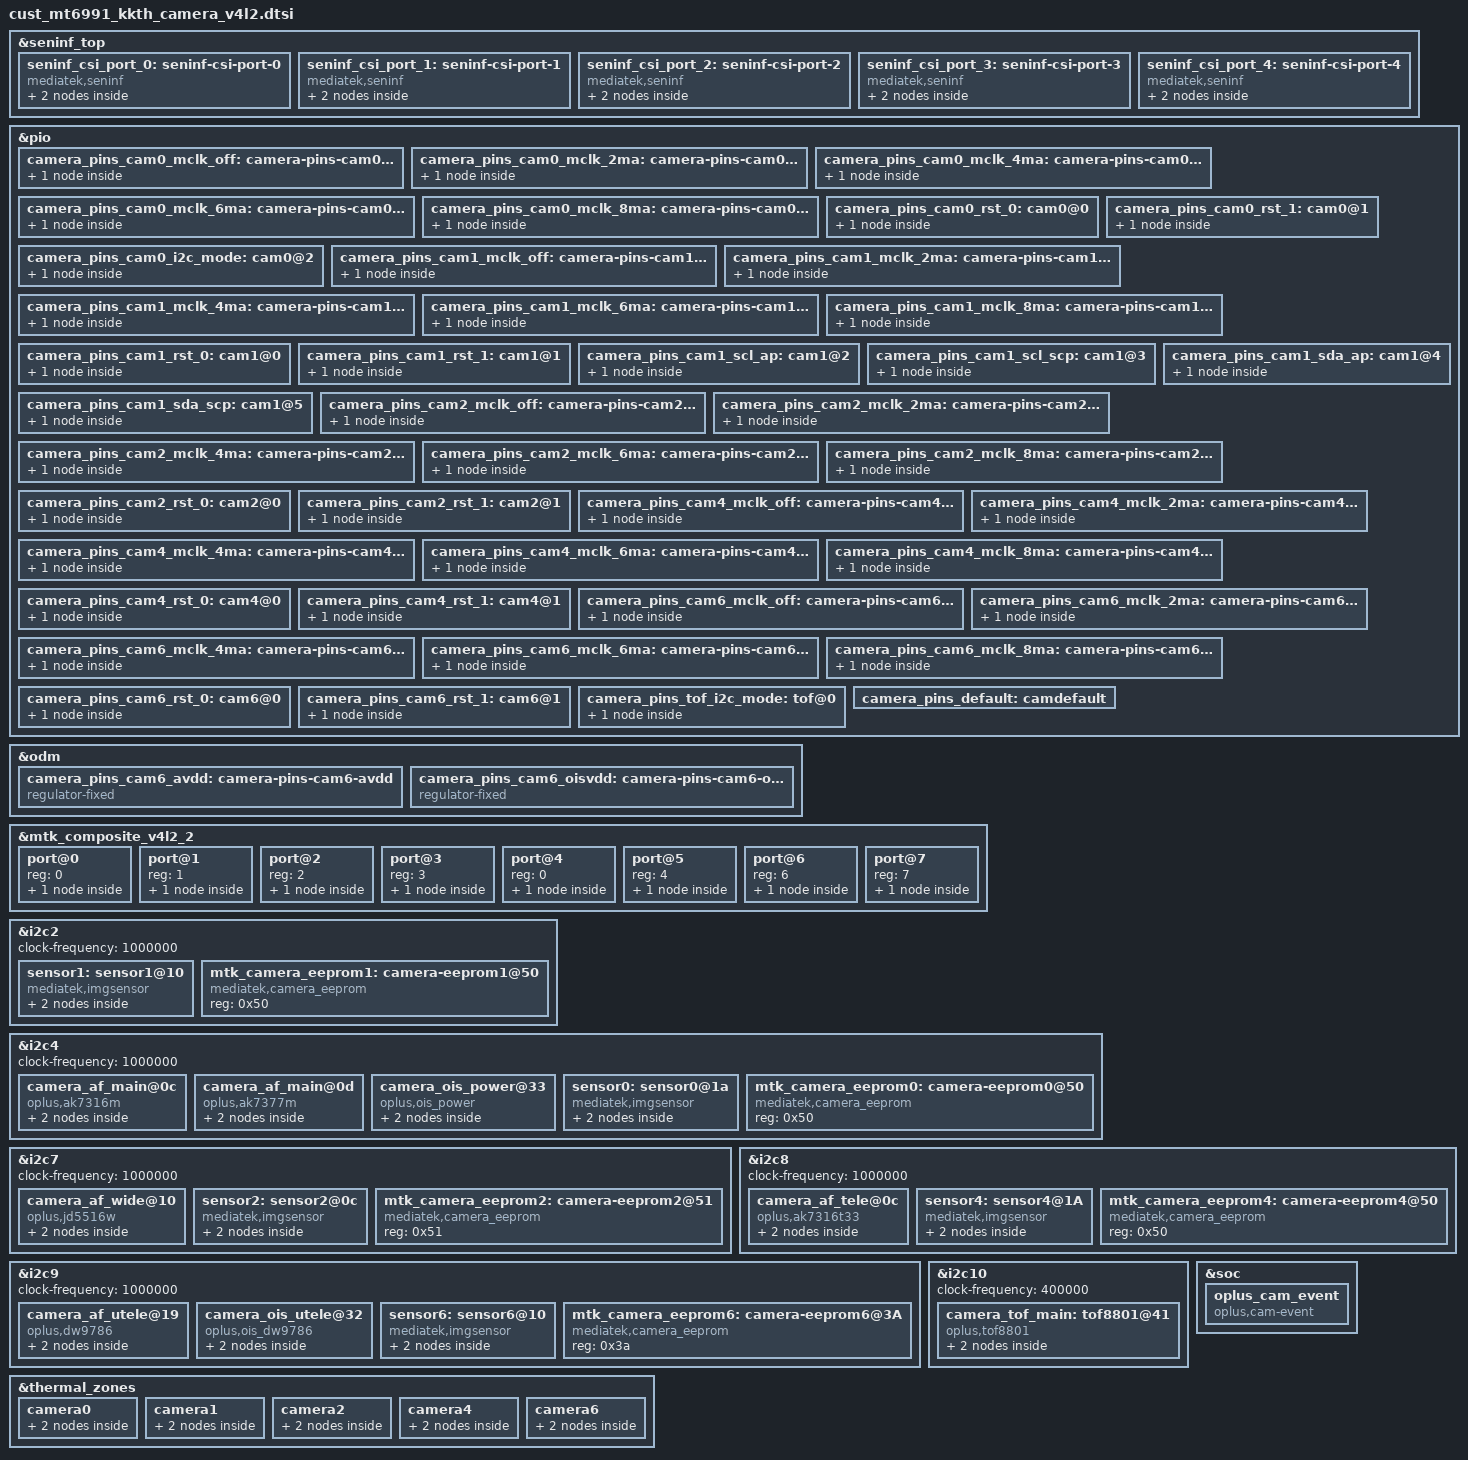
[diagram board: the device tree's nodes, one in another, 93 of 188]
// SPDX-License-Identifier: GPL-2.0
/* Copyright (c) 2023 MediaTek Inc. */
#include <dt-bindings/clock/mt6991-clk.h>
#include "mediatek/konka_regulator.dtsi"
// #include "mediatek/mt6373.dtsi"
&seninf_top {
		seninf_csi_port_0: seninf-csi-port-0 {
			compatible = "mediatek,seninf";
			csi-port = "0";

			// nvmem-cells = <&csi_efuse0>;
			nvmem-cell-names = "rg_csi";

			port {
				seninf_csi_port_0_in: endpoint {
					remote-endpoint = <&sensor0_out>;
				};
			};
		};

		seninf_csi_port_1: seninf-csi-port-1 {
			compatible = "mediatek,seninf";
			csi-port = "1";

			// nvmem-cells = <&csi_efuse1>;
			nvmem-cell-names = "rg_csi";

			port {
				seninf_csi_port_1_in: endpoint {
					remote-endpoint = <&sensor6_out>;
				};
			};
		};

		seninf_csi_port_2: seninf-csi-port-2 {
			compatible = "mediatek,seninf";
			csi-port = "2";

			// nvmem-cells = <&csi_efuse2>;
			nvmem-cell-names = "rg_csi";

			port {
				seninf_csi_port_2_in: endpoint {
					remote-endpoint = <&sensor4_out>;
				};
			};
		};
		seninf_csi_port_3: seninf-csi-port-3 {
			compatible = "mediatek,seninf";
			csi-port = "3";

			// nvmem-cells = <&csi_efuse3>;
			nvmem-cell-names = "rg_csi";

			port {
				seninf_csi_port_3_in: endpoint {
					remote-endpoint = <&sensor1_out>;
				};
			};
		};
		seninf_csi_port_4: seninf-csi-port-4 {
			compatible = "mediatek,seninf";
			csi-port = "4";

			// nvmem-cells = <&csi_efuse4>;
			nvmem-cell-names = "rg_csi";

			port {
				seninf_csi_port_4_in: endpoint {
					remote-endpoint = <&sensor2_out>;
				};
			};
		};
};

/* CAMERA GPIO standardization */
&pio {
	camera_pins_cam0_mclk_off: camera-pins-cam0-mclk-off {
		pins-cmd-dat {
			pinmux = <PINMUX_GPIO210__FUNC_GPIO210>;
			drive-strength = <1>;
		};
	};
	camera_pins_cam0_mclk_2ma: camera-pins-cam0-mclk-2ma {
		pins-cmd-dat {
			pinmux = <PINMUX_GPIO210__FUNC_CMMCLK4>;
			drive-strength = <0>;
		};
	};
	camera_pins_cam0_mclk_4ma: camera-pins-cam0-mclk-4ma {
		pins-cmd-dat {
			pinmux = <PINMUX_GPIO210__FUNC_CMMCLK4>;
			drive-strength = <1>;
		};
	};
	camera_pins_cam0_mclk_6ma: camera-pins-cam0-mclk-6ma {
		pins-cmd-dat {
			pinmux = <PINMUX_GPIO210__FUNC_CMMCLK4>;
			drive-strength = <2>;
		};
	};
	camera_pins_cam0_mclk_8ma: camera-pins-cam0-mclk-8ma {
		pins-cmd-dat {
			pinmux = <PINMUX_GPIO210__FUNC_CMMCLK4>;
			drive-strength = <3>;
		};
	};
	camera_pins_cam0_rst_0: cam0@0 {
		pins-cmd-dat {
			pinmux = <PINMUX_GPIO187__FUNC_GPIO187>;
			slew-rate = <1>;
			output-low;
		};
	};
	camera_pins_cam0_rst_1: cam0@1 {
		pins-cmd-dat {
			pinmux = <PINMUX_GPIO187__FUNC_GPIO187>;
			slew-rate = <1>;
			output-high;
		};
	};
	camera_pins_cam0_i2c_mode: cam0@2 {
		pins-cmd-dat {
			pinmux = <PINMUX_GPIO190__FUNC_SCL4>,
			<PINMUX_GPIO191__FUNC_SDA4>;
			bias-pull-up;
			input-enable;
		};
	};
	camera_pins_cam1_mclk_off: camera-pins-cam1-mclk-off {
		pins-cmd-dat {
			pinmux = <PINMUX_GPIO79__FUNC_GPIO79>;
			drive-strength = <1>;
		};
	};
	camera_pins_cam1_mclk_2ma: camera-pins-cam1-mclk-2ma {
		pins-cmd-dat {
			pinmux = <PINMUX_GPIO79__FUNC_CMMCLK0>;
			drive-strength = <0>;
		};
	};
	camera_pins_cam1_mclk_4ma: camera-pins-cam1-mclk-4ma {
		pins-cmd-dat {
			pinmux = <PINMUX_GPIO79__FUNC_CMMCLK0>;
			drive-strength = <1>;
		};
	};
	camera_pins_cam1_mclk_6ma: camera-pins-cam1-mclk-6ma {
		pins-cmd-dat {
			pinmux = <PINMUX_GPIO79__FUNC_CMMCLK0>;
			drive-strength = <2>;
		};
	};
	camera_pins_cam1_mclk_8ma: camera-pins-cam1-mclk-8ma {
		pins-cmd-dat {
			pinmux = <PINMUX_GPIO79__FUNC_CMMCLK0>;
			drive-strength = <3>;
		};
	};
	camera_pins_cam1_rst_0: cam1@0 {
		pins-cmd-dat {
			pinmux = <PINMUX_GPIO186__FUNC_GPIO186>;
			slew-rate = <1>;
			output-low;
		};
	};
	camera_pins_cam1_rst_1: cam1@1 {
		pins-cmd-dat {
			pinmux = <PINMUX_GPIO186__FUNC_GPIO186>;
			slew-rate = <1>;
			output-high;
		};
	};
	camera_pins_cam1_scl_ap: cam1@2 {
		pins-cmd-dat {
			pinmux = <PINMUX_GPIO188__FUNC_SCL2>;
		};
	};
	camera_pins_cam1_scl_scp: cam1@3 {
		pins-cmd-dat {
			pinmux = <PINMUX_GPIO188__FUNC_SCP_SCL8>;
		};
	};
	camera_pins_cam1_sda_ap: cam1@4 {
		pins-cmd-dat {
			pinmux = <PINMUX_GPIO189__FUNC_SDA2>;
		};
	};
	camera_pins_cam1_sda_scp: cam1@5 {
		pins-cmd-dat {
			pinmux = <PINMUX_GPIO189__FUNC_SCP_SDA8>;
		};
	};
	camera_pins_cam2_mclk_off: camera-pins-cam2-mclk-off {
		pins-cmd-dat {
			pinmux = <PINMUX_GPIO196__FUNC_GPIO196>;
			drive-strength = <1>;
		};
	};
	camera_pins_cam2_mclk_2ma: camera-pins-cam2-mclk-2ma {
		pins-cmd-dat {
			pinmux = <PINMUX_GPIO196__FUNC_CMMCLK3>;
			drive-strength = <0>;
		};
	};
	camera_pins_cam2_mclk_4ma: camera-pins-cam2-mclk-4ma {
		pins-cmd-dat {
			pinmux = <PINMUX_GPIO196__FUNC_CMMCLK3>;
			drive-strength = <1>;
		};
	};
	camera_pins_cam2_mclk_6ma: camera-pins-cam2-mclk-6ma {
		pins-cmd-dat {
			pinmux = <PINMUX_GPIO196__FUNC_CMMCLK3>;
			drive-strength = <2>;
		};
	};
	camera_pins_cam2_mclk_8ma: camera-pins-cam2-mclk-8ma {
		pins-cmd-dat {
			pinmux = <PINMUX_GPIO196__FUNC_CMMCLK3>;
			drive-strength = <3>;
		};
	};
	camera_pins_cam2_rst_0: cam2@0 {
		pins-cmd-dat {
			pinmux = <PINMUX_GPIO206__FUNC_GPIO206>;
			slew-rate = <1>;
			output-low;
		};
	};
	camera_pins_cam2_rst_1: cam2@1 {
		pins-cmd-dat {
			pinmux = <PINMUX_GPIO206__FUNC_GPIO206>;
			slew-rate = <1>;
			output-high;
		};
	};

	camera_pins_cam4_mclk_off: camera-pins-cam4-mclk-off {
		pins-cmd-dat {
			pinmux = <PINMUX_GPIO80__FUNC_GPIO80>;
			drive-strength = <1>;
		};
	};
	camera_pins_cam4_mclk_2ma: camera-pins-cam4-mclk-2ma {
		pins-cmd-dat {
			pinmux = <PINMUX_GPIO192__FUNC_CMMCLK2>;
			drive-strength = <0>;
		};
	};
	camera_pins_cam4_mclk_4ma: camera-pins-cam4-mclk-4ma {
		pins-cmd-dat {
			pinmux = <PINMUX_GPIO192__FUNC_CMMCLK2>;
			drive-strength = <1>;
		};
	};
	camera_pins_cam4_mclk_6ma: camera-pins-cam4-mclk-6ma {
		pins-cmd-dat {
			pinmux = <PINMUX_GPIO192__FUNC_CMMCLK2>;
			drive-strength = <2>;
		};
	};
	camera_pins_cam4_mclk_8ma: camera-pins-cam4-mclk-8ma {
		pins-cmd-dat {
			pinmux = <PINMUX_GPIO192__FUNC_CMMCLK2>;
			drive-strength = <3>;
		};
	};
	camera_pins_cam4_rst_0: cam4@0 {
		pins-cmd-dat {
			pinmux = <PINMUX_GPIO197__FUNC_GPIO197>;
			slew-rate = <1>;
			output-low;
		};
	};
	camera_pins_cam4_rst_1: cam4@1 {
		pins-cmd-dat {
			pinmux = <PINMUX_GPIO197__FUNC_GPIO197>;
			slew-rate = <1>;
			output-high;
		};
	};

	camera_pins_cam6_mclk_off: camera-pins-cam6-mclk-off {
		pins-cmd-dat {
			pinmux = <PINMUX_GPIO80__FUNC_GPIO80>;
			drive-strength = <1>;
		};
	};
	camera_pins_cam6_mclk_2ma: camera-pins-cam6-mclk-2ma {
		pins-cmd-dat {
			pinmux = <PINMUX_GPIO80__FUNC_CMMCLK1>;
			drive-strength = <0>;
		};
	};
	camera_pins_cam6_mclk_4ma: camera-pins-cam6-mclk-4ma {
		pins-cmd-dat {
			pinmux = <PINMUX_GPIO80__FUNC_CMMCLK1>;
			drive-strength = <1>;
		};
	};
	camera_pins_cam6_mclk_6ma: camera-pins-cam6-mclk-6ma {
		pins-cmd-dat {
			pinmux = <PINMUX_GPIO80__FUNC_CMMCLK1>;
			drive-strength = <2>;
		};
	};
	camera_pins_cam6_mclk_8ma: camera-pins-cam6-mclk-8ma {
		pins-cmd-dat {
			pinmux = <PINMUX_GPIO80__FUNC_CMMCLK1>;
			drive-strength = <3>;
		};
	};
	camera_pins_cam6_rst_0: cam6@0 {
		pins-cmd-dat {
			pinmux = <PINMUX_GPIO193__FUNC_GPIO193>;
			slew-rate = <1>;
			output-low;
		};
	};
	camera_pins_cam6_rst_1: cam6@1 {
		pins-cmd-dat {
			pinmux = <PINMUX_GPIO193__FUNC_GPIO193>;
			slew-rate = <1>;
			output-high;
		};
	};
	camera_pins_tof_i2c_mode: tof@0 {
		pins-cmd-dat {
			pinmux = <PINMUX_GPIO101__FUNC_SCL10>,
			<PINMUX_GPIO102__FUNC_SDA10>,
			<PINMUX_GPIO21__FUNC_GPIO21>;
			bias-pull-up;
			input-enable;
		};
	};
	camera_pins_default: camdefault {
	};
};
/* CAMERA GPIO end */

&odm {
	camera_pins_cam6_avdd: camera-pins-cam6-avdd {
		compatible = "regulator-fixed";
		regulator-name = "camera-pins-cam6-avdd";
		regulator-min-microvolt = <2800000>;
		regulator-max-microvolt = <2800000>;
		enable-active-high;
		gpio = <&pio 183 0x0>;
	};
	camera_pins_cam6_oisvdd: camera-pins-cam6-oisvdd {
		compatible = "regulator-fixed";
		regulator-name = "camera-pins-cam6-oisvdd";
		regulator-min-microvolt = <3100000>;
		regulator-max-microvolt = <3100000>;
		enable-active-high;
		gpio = <&pio 180 0x0>;
	};
};

&mtk_composite_v4l2_2 {

	#address-cells = <1>;
	#size-cells = <0>;

	port@0 {
		reg = <0>;
		main_af_endpoint: endpoint {
			remote-endpoint = <&main_af>;
		};
	};
	port@1 {
		reg = <1>;
		wide_af_endpoint: endpoint {
			remote-endpoint = <&wide_af>;
		};
	};
	port@2 {
		reg = <2>;
		tele_af_endpoint: endpoint {
			remote-endpoint = <&tele_af>;
		};
	};
	port@3 {
		reg = <3>;
		utele_af_endpoint: endpoint {
			remote-endpoint = <&utele_af>;
		};
	};
	port@4 {
		reg = <0>;
		main_tof_endpoint: endpoint {
			remote-endpoint = <&main_tof>;
		};
	};
	port@5 {
		reg = <4>;
		utele_ois_endpoint: endpoint {
			remote-endpoint = <&utele_ois>;
		};
	};
	port@6 {
		reg = <6>;
		main_af2_endpoint: endpoint {
			remote-endpoint = <&main_af2>;
		};
	};
	port@7 {
		reg = <7>;
		ois_power_endpoint: endpoint {
			remote-endpoint = <&ois_power>;
		};
	};
};


&i2c2 {
	status = "okay";
	clock-frequency = <1000000>;
	#address-cells = <1>;
	#size-cells = <0>;

	sensor1: sensor1@10 {
		compatible = "mediatek,imgsensor";
		sensor-names = "kkthfront_mipi_raw";
		reg = <0x10>;
		#thermal-sensor-cells = <0>;

		pinctrl-names = "mclk_off",
				"mclk_2mA",
				"mclk_4mA",
				"mclk_6mA",
				"mclk_8mA",
				"rst_low",
				"rst_high",
				"scl_ap",
				"scl_scp",
				"sda_ap",
				"sda_scp";

		pinctrl-0 = <&camera_pins_cam1_mclk_off>;
		pinctrl-1 = <&camera_pins_cam1_mclk_2ma>;
		pinctrl-2 = <&camera_pins_cam1_mclk_4ma>;
		pinctrl-3 = <&camera_pins_cam1_mclk_6ma>;
		pinctrl-4 = <&camera_pins_cam1_mclk_8ma>;
		pinctrl-5 = <&camera_pins_cam1_rst_0>;
		pinctrl-6 = <&camera_pins_cam1_rst_1>;
		pinctrl-7 = <&camera_pins_cam1_scl_ap>;
		pinctrl-8 = <&camera_pins_cam1_scl_scp>;
		pinctrl-9 = <&camera_pins_cam1_sda_ap>;
		pinctrl-10 = <&camera_pins_cam1_sda_scp>;

		avdd-supply = <&wl28681c_konka_ldo3a>;
		dvdd-supply = <&wl28681c_konka_ldo1a>;
		dovdd-supply = <&mt6373_vrf18_aif>;

		clocks =<&cksys_clk CLK_CK_UNIVPLL_192M_D32>,
			<&cksys_clk CLK_CK_UNIVPLL_192M_D16>,
			<&cksys_clk CLK_CK_F26M_CK_D2>,
			<&cksys_clk CLK_CK_UNIVPLL_192M_D10>,
			<&cksys_clk CLK_CK_UNIVPLL_192M_D8>,
			<&cksys_clk CLK_CK_UNIVPLL_D6_D16>,
			<&cksys_clk CLK_CK_OSC3>,
			<&cksys_clk CLK_CK_UNIVPLL_D6_D8>,
			<&vlp_cksys_clk CLK_VLP_CK_CAMTG0_SEL>;
		clock-names ="6", "12", "13", "19.2",
			"24", "26", "26_ulposc", "52", "mclk";

		status = "okay";
		port {
			sensor1_out: endpoint {
				remote-endpoint = <&seninf_csi_port_3_in>;
			};
		};
	};

	mtk_camera_eeprom1:camera-eeprom1@50 {
		compatible = "mediatek,camera_eeprom";
		reg = <0x50>;
		status = "okay";
	};
};


&i2c4 {
	status = "okay";
	clock-frequency = <1000000>;
	#address-cells = <1>;
	#size-cells = <0>;

	camera_af_main@0c {
		compatible = "oplus,ak7316m";
		reg = <0x0c>;
		vin-supply = <&mt6373_vcn33_3>;
		port {
			main_af: endpoint {
				remote-endpoint = <&main_af_endpoint>;
			};
		};
	};

	camera_af_main@0d {
		compatible = "oplus,ak7377m";
		reg = <0x0d>;
		vin-supply = <&mt6373_vcn33_3>;
		port {
			main_af2: endpoint {
				remote-endpoint = <&main_af2_endpoint>;
			};
		};
	};

	camera_ois_power@33 {
		compatible = "oplus,ois_power";
		reg = <0x33>;
		ois1-supply = <&mt6373_vcn33_3>;
		ois2-supply = <&mt6373_vcn33_2>;
		port {
			ois_power: endpoint {
				remote-endpoint = <&ois_power_endpoint>;
			};
		};
	};

	sensor0: sensor0@1a {
		compatible = "mediatek,imgsensor";
		sensor-names = "kkthmain_mipi_raw";
		reg = <0x1a>;
		#thermal-sensor-cells = <0>;

		pinctrl-names = "mclk_off",
				"mclk_2mA",
				"mclk_4mA",
				"mclk_6mA",
				"mclk_8mA",
				"rst_low",
				"rst_high",
				"default";
		pinctrl-0 = <&camera_pins_cam0_mclk_off>;
		pinctrl-1 = <&camera_pins_cam0_mclk_2ma>;
		pinctrl-2 = <&camera_pins_cam0_mclk_4ma>;
		pinctrl-3 = <&camera_pins_cam0_mclk_6ma>;
		pinctrl-4 = <&camera_pins_cam0_mclk_8ma>;
		pinctrl-5 = <&camera_pins_cam0_rst_0>;
		pinctrl-6 = <&camera_pins_cam0_rst_1>;
		pinctrl-7 = <&camera_pins_cam0_i2c_mode>;

		avdd1-supply = <&wl28681c_konka_ldo7a>;
		avdd-supply = <&wl28681c_konka_ldo4a>;
		dvdd-supply = <&wl28681c_konka_ldo2a>;
		dovdd-supply = <&mt6373_vrf18_aif>;
		afvdd-supply = <&mt6373_vcn33_3>;

		clocks = <&cksys_clk CLK_CK_UNIVPLL_192M_D32>,
			<&cksys_clk CLK_CK_UNIVPLL_192M_D16>,
			<&cksys_clk CLK_CK_F26M_CK_D2>,
			<&cksys_clk CLK_CK_UNIVPLL_192M_D10>,
			<&cksys_clk CLK_CK_UNIVPLL_192M_D8>,
			<&cksys_clk CLK_CK_UNIVPLL_D6_D16>,
			<&cksys_clk CLK_CK_UNIVPLL_D6_D8>,
			<&vlp_cksys_clk CLK_VLP_CK_CAMTG4_SEL>;
		clock-names = "6", "12", "13", "19.2", "24", "26", "52", "mclk";

		status = "okay";

		port {
			sensor0_out: endpoint {
				remote-endpoint = <&seninf_csi_port_0_in>;
			};
		};
	};

	mtk_camera_eeprom0:camera-eeprom0@50 {
		compatible = "mediatek,camera_eeprom";
		reg = <0x50>;
		status = "okay";
	};
};

&i2c7 {
	status = "okay";
	clock-frequency = <1000000>;
	#address-cells = <1>;
	#size-cells = <0>;

	camera_af_wide@10 {
		compatible = "oplus,jd5516w";
		reg = <0x10>;
		vin-supply = <&wl28681c_konka_ldo6a>;
		port {
			wide_af: endpoint {
				remote-endpoint = <&wide_af_endpoint>;
			};
		};
	};

	sensor2: sensor2@0c {
		compatible = "mediatek,imgsensor";
		sensor-names = "kkthuwide_mipi_raw";
		reg = <0x0c>;
		#thermal-sensor-cells = <0>;

		pinctrl-names = "mclk_off",
				"mclk_2mA",
				"mclk_4mA",
				"mclk_6mA",
				"mclk_8mA",
				"rst_low",
				"rst_high";
		pinctrl-0 = <&camera_pins_cam2_mclk_off>;
		pinctrl-1 = <&camera_pins_cam2_mclk_2ma>;
		pinctrl-2 = <&camera_pins_cam2_mclk_4ma>;
		pinctrl-3 = <&camera_pins_cam2_mclk_6ma>;
		pinctrl-4 = <&camera_pins_cam2_mclk_8ma>;
		pinctrl-5 = <&camera_pins_cam2_rst_0>;
		pinctrl-6 = <&camera_pins_cam2_rst_1>;

		avdd-supply = <&wl28681c_konka_ldo5a>;
		dvdd-supply = <&mt6373_vrf13_aif>;
		dovdd-supply = <&mt6373_vrf18_aif>;
		afvdd-supply = <&wl28681c_konka_ldo6a>;

		clocks = <&cksys_clk CLK_CK_UNIVPLL_192M_D32>,
			<&cksys_clk CLK_CK_UNIVPLL_192M_D16>,
			<&cksys_clk CLK_CK_F26M_CK_D2>,
			<&cksys_clk CLK_CK_UNIVPLL_192M_D10>,
			<&cksys_clk CLK_CK_UNIVPLL_192M_D8>,
			<&cksys_clk CLK_CK_UNIVPLL_D6_D16>,
			<&cksys_clk CLK_CK_UNIVPLL_D6_D8>,
			<&vlp_cksys_clk CLK_VLP_CK_CAMTG3_SEL>;
		clock-names = "6", "12", "13", "19.2", "24", "26", "52", "mclk";

		status = "okay";

		port {
			sensor2_out: endpoint {
				remote-endpoint = <&seninf_csi_port_4_in>;
			};
		};
	};

	mtk_camera_eeprom2:camera-eeprom2@51 {
		compatible = "mediatek,camera_eeprom";
		reg = <0x51>;
		status = "okay";
	};
};


&i2c8 {
	status = "okay";
	clock-frequency = <1000000>;
	#address-cells = <1>;
	#size-cells = <0>;

	camera_af_tele@0c {
		compatible = "oplus,ak7316t33";
		reg = <0x0c>;
		vin-supply = <&mt6373_vcn33_2>;
		port {
			tele_af: endpoint {
				remote-endpoint = <&tele_af_endpoint>;
			};
		};
	};

	sensor4: sensor4@1A {
		compatible = "mediatek,imgsensor";
		sensor-names = "kkthtele_mipi_raw";
		reg = <0x1A>;
		#thermal-sensor-cells = <0>;

		pinctrl-names = "mclk_off",
				"mclk_2mA",
				"mclk_4mA",
				"mclk_6mA",
				"mclk_8mA",
				"rst_low",
				"rst_high";
		pinctrl-0 = <&camera_pins_cam4_mclk_off>;
		pinctrl-1 = <&camera_pins_cam4_mclk_2ma>;
		pinctrl-2 = <&camera_pins_cam4_mclk_4ma>;
		pinctrl-3 = <&camera_pins_cam4_mclk_6ma>;
		pinctrl-4 = <&camera_pins_cam4_mclk_8ma>;
		pinctrl-5 = <&camera_pins_cam4_rst_0>;
		pinctrl-6 = <&camera_pins_cam4_rst_1>;

		avdd-supply = <&wl28681c_konka_ldo3a>;
		dvdd-supply = <&wl28681c_konka_ldo1a>;
		dovdd-supply = <&mt6373_vrf18_aif>;
		afvdd-supply = <&mt6373_vcn33_2>;

		clocks = <&cksys_clk CLK_CK_UNIVPLL_192M_D32>,
			<&cksys_clk CLK_CK_UNIVPLL_192M_D16>,
			<&cksys_clk CLK_CK_F26M_CK_D2>,
			<&cksys_clk CLK_CK_UNIVPLL_192M_D10>,
			<&cksys_clk CLK_CK_UNIVPLL_192M_D8>,
			<&cksys_clk CLK_CK_UNIVPLL_D6_D16>,
			<&cksys_clk CLK_CK_UNIVPLL_D6_D8>,
			<&vlp_cksys_clk CLK_VLP_CK_CAMTG2_SEL>;
		clock-names = "6", "12", "13", "19.2", "24", "26", "52", "mclk";

		status = "okay";

		port {
			sensor4_out: endpoint {
				remote-endpoint = <&seninf_csi_port_2_in>;
			};
		};
	};
	mtk_camera_eeprom4:camera-eeprom4@50 {
		compatible = "mediatek,camera_eeprom";
		reg = <0x50>;
		status = "okay";
	};
};



&i2c9 {
	status = "okay";
	clock-frequency = <1000000>;
	#address-cells = <1>;
	#size-cells = <0>;

	camera_af_utele@19 {
		compatible = "oplus,dw9786";
		reg = <0x19>;
		iovdd-supply = <&mt6373_vrf18_aif>;
		afvdd-supply = <&mt6373_vcn33_1>;
		oisvdd-supply = <&camera_pins_cam6_oisvdd>;
		port {
			utele_af: endpoint {
				remote-endpoint = <&utele_af_endpoint>;
			};
		};
	};

	camera_ois_utele@32 {
		compatible = "oplus,ois_dw9786";
		reg = <0x32>;
		iovdd-supply = <&mt6373_vrf18_aif>;
		afvdd-supply = <&mt6373_vcn33_1>;
		oisvdd-supply = <&camera_pins_cam6_oisvdd>;
		port {
			utele_ois: endpoint {
				remote-endpoint = <&utele_ois_endpoint>;
			};
		};
	};

	sensor6: sensor6@10 {
		compatible = "mediatek,imgsensor";
		sensor-names = "konkautele_mipi_raw";
		reg = <0x10>;
		#thermal-sensor-cells = <0>;

		pinctrl-names = "mclk_off",
				"mclk_2mA",
				"mclk_4mA",
				"mclk_6mA",
				"mclk_8mA",
				"rst_low",
				"rst_high";
		pinctrl-0 = <&camera_pins_cam6_mclk_off>;
		pinctrl-1 = <&camera_pins_cam6_mclk_2ma>;
		pinctrl-2 = <&camera_pins_cam6_mclk_4ma>;
		pinctrl-3 = <&camera_pins_cam6_mclk_6ma>;
		pinctrl-4 = <&camera_pins_cam6_mclk_8ma>;
		pinctrl-5 = <&camera_pins_cam6_rst_0>;
		pinctrl-6 = <&camera_pins_cam6_rst_1>;

		avdd-supply = <&camera_pins_cam6_avdd>;
		dvdd-supply = <&mt6373_vrf12_aif>;
		dovdd-supply = <&mt6373_vrf18_aif>;
		afvdd-supply = <&mt6373_vcn33_1>;
		oisvdd-supply = <&camera_pins_cam6_oisvdd>;

		clocks = <&cksys_clk CLK_CK_UNIVPLL_192M_D32>,
			<&cksys_clk CLK_CK_UNIVPLL_192M_D16>,
			<&cksys_clk CLK_CK_F26M_CK_D2>,
			<&cksys_clk CLK_CK_UNIVPLL_192M_D10>,
			<&cksys_clk CLK_CK_UNIVPLL_192M_D8>,
			<&cksys_clk CLK_CK_UNIVPLL_D6_D16>,
			<&cksys_clk CLK_CK_UNIVPLL_D6_D8>,
			<&vlp_cksys_clk CLK_VLP_CK_CAMTG1_SEL>;
		clock-names = "6", "12", "13", "19.2", "24", "26", "52", "mclk";

		status = "okay";

		port {
			sensor6_out: endpoint {
				remote-endpoint = <&seninf_csi_port_1_in>;
			};
		};
	};

	mtk_camera_eeprom6:camera-eeprom6@3A{
		compatible = "mediatek,camera_eeprom";
		reg = <0x3a>;
		status = "okay";
	};
};

&i2c10 {
	clock-frequency = <400000>;
	#address-cells = <1>;
	#size-cells = <0>;
	camera_tof_main:tof8801@41 {
		compatible = "oplus,tof8801";
		pinctrl-names = "default";
		pinctrl-0 = <&camera_pins_tof_i2c_mode>;
		#address-cells = <1>;
		#size-cells = <0>;
		reg = <0x41>;
		enable-gpio = <&pio 21 0x0>;
		port {
			main_tof: endpoint {
				remote-endpoint = <&main_tof_endpoint>;
			};
		};
	};
};

&thermal_zones {
	camera0: camera0 {
		polling-delay = <0>; /* milliseconds */
		polling-delay-passive = <0>; /* milliseconds */
		thermal-sensors = <&sensor0>;
		trips {
			camera0_crit: camera0-crit {
				temperature = <120000>;
				hysteresis = <2000>;
				type = "passive";
			};
		};
	};
	camera1: camera1 {
		polling-delay = <0>; /* milliseconds */
		polling-delay-passive = <0>; /* milliseconds */
		thermal-sensors = <&sensor1>;
		trips {
			camera1_crit: camera1-crit {
				temperature = <120000>;
				hysteresis = <2000>;
				type = "passive";
			};
		};
	};
	camera2: camera2 {
		polling-delay = <0>; /* milliseconds */
		polling-delay-passive = <0>; /* milliseconds */
		thermal-sensors = <&sensor2>;
		trips {
			camera2_crit: camera2-crit {
				temperature = <120000>;
				hysteresis = <2000>;
				type = "passive";
			};
		};
	};
	camera4: camera4 {
		polling-delay = <0>; /* milliseconds */
		polling-delay-passive = <0>; /* milliseconds */
		thermal-sensors = <&sensor4>;
		trips {
			camera4_crit: camera4-crit {
				temperature = <120000>;
				hysteresis = <2000>;
				type = "passive";
			};
		};
	};
	camera6: camera6 {
		polling-delay = <0>;
		polling-delay-passive = <0>;
		thermal-sensors = <&sensor6>;
		trips {
			camera6_crit: camera6-crit {
				temperature = <120000>;
				hysteresis = <2000>;
				type = "passive";
			};
		};
	};
};

&soc {
	//#ifdef OPLUS_FEATURE_CAMERA_COMMON
	oplus_cam_event:oplus_cam_event {
		compatible = "oplus,cam-event";
	};
	//#endif /* OPLUS_FEATURE_CAMERA_COMMON */
};
